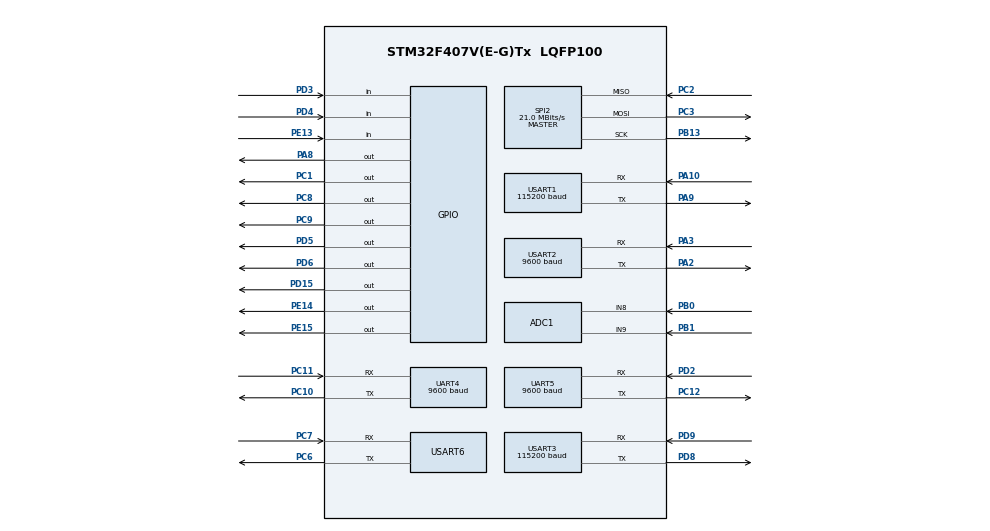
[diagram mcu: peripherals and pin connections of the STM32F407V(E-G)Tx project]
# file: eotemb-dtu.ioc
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ADC1.Channel-0\#ChannelRegularConversion=ADC_CHANNEL_8
ADC1.Channel-1\#ChannelRegularConversion=ADC_CHANNEL_9
ADC1.ClockPrescaler=ADC_CLOCK_SYNC_PCLK_DIV6
ADC1.ContinuousConvMode=ENABLE
ADC1.DMAContinuousRequests=ENABLE
ADC1.InjNumberOfConversion=0
ADC1.NbrOfConversion=2
ADC1.NbrOfConversionFlag=1
ADC1.Rank-0\#ChannelRegularConversion=1
ADC1.Rank-1\#ChannelRegularConversion=2
ADC1.SamplingTime-0\#ChannelRegularConversion=ADC_SAMPLETIME_480CYCLES
ADC1.SamplingTime-1\#ChannelRegularConversion=ADC_SAMPLETIME_480CYCLES
ADC1.master=1
Dma.ADC1.10.Direction=DMA_PERIPH_TO_MEMORY
Dma.ADC1.10.FIFOMode=DMA_FIFOMODE_DISABLE
Dma.ADC1.10.Instance=DMA2_Stream0
Dma.ADC1.10.MemDataAlignment=DMA_MDATAALIGN_HALFWORD
Dma.ADC1.10.MemInc=DMA_MINC_ENABLE
Dma.ADC1.10.Mode=DMA_CIRCULAR
Dma.ADC1.10.PeriphDataAlignment=DMA_PDATAALIGN_HALFWORD
Dma.ADC1.10.PeriphInc=DMA_PINC_DISABLE
Dma.ADC1.10.Priority=DMA_PRIORITY_LOW
Dma.Request0=USART1_RX
Dma.Request1=USART3_RX
Dma.Request10=ADC1
Dma.Request11=USART1_TX
Dma.Request2=USART6_RX
Dma.Request3=UART5_RX
Dma.Request4=UART4_RX
Dma.Request5=USART2_RX
Dma.Request6=UART5_TX
Dma.Request7=USART2_TX
Dma.Request8=USART3_TX
Dma.Request9=UART4_TX
Dma.UART4_RX.4.Direction=DMA_PERIPH_TO_MEMORY
Dma.UART4_RX.4.FIFOMode=DMA_FIFOMODE_DISABLE
Dma.UART4_RX.4.Instance=DMA1_Stream2
Dma.UART4_RX.4.MemDataAlignment=DMA_MDATAALIGN_BYTE
Dma.UART4_RX.4.MemInc=DMA_MINC_ENABLE
Dma.UART4_RX.4.Mode=DMA_NORMAL
Dma.UART4_RX.4.PeriphDataAlignment=DMA_PDATAALIGN_BYTE
Dma.UART4_RX.4.PeriphInc=DMA_PINC_DISABLE
Dma.UART4_RX.4.Priority=DMA_PRIORITY_LOW
Dma.UART4_TX.9.Direction=DMA_MEMORY_TO_PERIPH
Dma.UART4_TX.9.FIFOMode=DMA_FIFOMODE_DISABLE
Dma.UART4_TX.9.Instance=DMA1_Stream4
Dma.UART4_TX.9.MemDataAlignment=DMA_MDATAALIGN_BYTE
Dma.UART4_TX.9.MemInc=DMA_MINC_ENABLE
Dma.UART4_TX.9.Mode=DMA_NORMAL
Dma.UART4_TX.9.PeriphDataAlignment=DMA_PDATAALIGN_BYTE
Dma.UART4_TX.9.PeriphInc=DMA_PINC_DISABLE
Dma.UART4_TX.9.Priority=DMA_PRIORITY_LOW
Dma.UART5_RX.3.Direction=DMA_PERIPH_TO_MEMORY
Dma.UART5_RX.3.FIFOMode=DMA_FIFOMODE_DISABLE
Dma.UART5_RX.3.Instance=DMA1_Stream0
Dma.UART5_RX.3.MemDataAlignment=DMA_MDATAALIGN_BYTE
Dma.UART5_RX.3.MemInc=DMA_MINC_ENABLE
Dma.UART5_RX.3.Mode=DMA_NORMAL
Dma.UART5_RX.3.PeriphDataAlignment=DMA_PDATAALIGN_BYTE
Dma.UART5_RX.3.PeriphInc=DMA_PINC_DISABLE
Dma.UART5_RX.3.Priority=DMA_PRIORITY_LOW
Dma.UART5_TX.6.Direction=DMA_MEMORY_TO_PERIPH
Dma.UART5_TX.6.FIFOMode=DMA_FIFOMODE_DISABLE
Dma.UART5_TX.6.Instance=DMA1_Stream7
Dma.UART5_TX.6.MemDataAlignment=DMA_MDATAALIGN_BYTE
Dma.UART5_TX.6.MemInc=DMA_MINC_ENABLE
Dma.UART5_TX.6.Mode=DMA_NORMAL
Dma.UART5_TX.6.PeriphDataAlignment=DMA_PDATAALIGN_BYTE
Dma.UART5_TX.6.PeriphInc=DMA_PINC_DISABLE
Dma.UART5_TX.6.Priority=DMA_PRIORITY_LOW
Dma.USART1_RX.0.Direction=DMA_PERIPH_TO_MEMORY
Dma.USART1_RX.0.FIFOMode=DMA_FIFOMODE_DISABLE
Dma.USART1_RX.0.Instance=DMA2_Stream2
Dma.USART1_RX.0.MemDataAlignment=DMA_MDATAALIGN_BYTE
Dma.USART1_RX.0.MemInc=DMA_MINC_ENABLE
Dma.USART1_RX.0.Mode=DMA_NORMAL
Dma.USART1_RX.0.PeriphDataAlignment=DMA_PDATAALIGN_BYTE
Dma.USART1_RX.0.PeriphInc=DMA_PINC_DISABLE
Dma.USART1_RX.0.Priority=DMA_PRIORITY_LOW
Dma.USART1_TX.11.Direction=DMA_MEMORY_TO_PERIPH
Dma.USART1_TX.11.FIFOMode=DMA_FIFOMODE_DISABLE
Dma.USART1_TX.11.Instance=DMA2_Stream7
Dma.USART1_TX.11.MemDataAlignment=DMA_MDATAALIGN_BYTE
Dma.USART1_TX.11.MemInc=DMA_MINC_ENABLE
Dma.USART1_TX.11.Mode=DMA_NORMAL
Dma.USART1_TX.11.PeriphDataAlignment=DMA_PDATAALIGN_BYTE
Dma.USART1_TX.11.PeriphInc=DMA_PINC_DISABLE
Dma.USART1_TX.11.Priority=DMA_PRIORITY_LOW
Dma.USART2_RX.5.Direction=DMA_PERIPH_TO_MEMORY
Dma.USART2_RX.5.FIFOMode=DMA_FIFOMODE_DISABLE
Dma.USART2_RX.5.Instance=DMA1_Stream5
Dma.USART2_RX.5.MemDataAlignment=DMA_MDATAALIGN_BYTE
Dma.USART2_RX.5.MemInc=DMA_MINC_ENABLE
Dma.USART2_RX.5.Mode=DMA_NORMAL
Dma.USART2_RX.5.PeriphDataAlignment=DMA_PDATAALIGN_BYTE
Dma.USART2_RX.5.PeriphInc=DMA_PINC_DISABLE
Dma.USART2_RX.5.Priority=DMA_PRIORITY_LOW
Dma.USART2_TX.7.Direction=DMA_MEMORY_TO_PERIPH
Dma.USART2_TX.7.FIFOMode=DMA_FIFOMODE_DISABLE
Dma.USART2_TX.7.Instance=DMA1_Stream6
Dma.USART2_TX.7.MemDataAlignment=DMA_MDATAALIGN_BYTE
Dma.USART2_TX.7.MemInc=DMA_MINC_ENABLE
Dma.USART2_TX.7.Mode=DMA_NORMAL
Dma.USART2_TX.7.PeriphDataAlignment=DMA_PDATAALIGN_BYTE
Dma.USART2_TX.7.PeriphInc=DMA_PINC_DISABLE
Dma.USART2_TX.7.Priority=DMA_PRIORITY_LOW
Dma.USART3_RX.1.Direction=DMA_PERIPH_TO_MEMORY
Dma.USART3_RX.1.FIFOMode=DMA_FIFOMODE_DISABLE
Dma.USART3_RX.1.Instance=DMA1_Stream1
Dma.USART3_RX.1.MemDataAlignment=DMA_MDATAALIGN_BYTE
Dma.USART3_RX.1.MemInc=DMA_MINC_ENABLE
Dma.USART3_RX.1.Mode=DMA_NORMAL
Dma.USART3_RX.1.PeriphDataAlignment=DMA_PDATAALIGN_BYTE
Dma.USART3_RX.1.PeriphInc=DMA_PINC_DISABLE
Dma.USART3_RX.1.Priority=DMA_PRIORITY_LOW
Dma.USART3_TX.8.Direction=DMA_MEMORY_TO_PERIPH
Dma.USART3_TX.8.FIFOMode=DMA_FIFOMODE_DISABLE
Dma.USART3_TX.8.Instance=DMA1_Stream3
Dma.USART3_TX.8.MemDataAlignment=DMA_MDATAALIGN_BYTE
Dma.USART3_TX.8.MemInc=DMA_MINC_ENABLE
Dma.USART3_TX.8.Mode=DMA_NORMAL
Dma.USART3_TX.8.PeriphDataAlignment=DMA_PDATAALIGN_BYTE
Dma.USART3_TX.8.PeriphInc=DMA_PINC_DISABLE
Dma.USART3_TX.8.Priority=DMA_PRIORITY_LOW
Dma.USART6_RX.2.Direction=DMA_PERIPH_TO_MEMORY
Dma.USART6_RX.2.FIFOMode=DMA_FIFOMODE_DISABLE
Dma.USART6_RX.2.Instance=DMA2_Stream1
Dma.USART6_RX.2.MemDataAlignment=DMA_MDATAALIGN_BYTE
Dma.USART6_RX.2.MemInc=DMA_MINC_ENABLE
Dma.USART6_RX.2.Mode=DMA_NORMAL
Dma.USART6_RX.2.PeriphDataAlignment=DMA_PDATAALIGN_BYTE
Dma.USART6_RX.2.PeriphInc=DMA_PINC_DISABLE
Dma.USART6_RX.2.Priority=DMA_PRIORITY_LOW
FREERTOS.Tasks01=defaultTask,0,128,StartDefaultTask,Default,NULL,Dynamic,NULL,NULL
FREERTOS.configUSE_NEWLIB_REENTRANT=1
IWDG.Prescaler=IWDG_PRESCALER_256
Mcu.Family=STM32F4
Mcu.Name=STM32F407V(E-G)Tx
Mcu.Package=LQFP100
NVIC.DMA1_Stream0_IRQn=true\:5\:0\:false\:false\:true\:true\:false\:true\:true
NVIC.DMA1_Stream1_IRQn=true\:5\:0\:false\:false\:true\:true\:false\:true\:true
NVIC.DMA1_Stream2_IRQn=true\:5\:0\:false\:false\:true\:true\:false\:true\:true
NVIC.DMA1_Stream3_IRQn=true\:5\:0\:false\:false\:true\:true\:false\:true\:true
NVIC.DMA1_Stream4_IRQn=true\:5\:0\:false\:false\:true\:true\:false\:true\:true
NVIC.DMA1_Stream5_IRQn=true\:5\:0\:false\:false\:true\:true\:false\:true\:true
NVIC.DMA1_Stream6_IRQn=true\:5\:0\:false\:false\:true\:true\:false\:true\:true
NVIC.DMA1_Stream7_IRQn=true\:5\:0\:false\:false\:true\:true\:false\:true\:true
NVIC.DMA2_Stream0_IRQn=true\:5\:0\:false\:false\:true\:true\:false\:true\:true
NVIC.DMA2_Stream1_IRQn=true\:5\:0\:false\:false\:true\:true\:false\:true\:true
NVIC.DMA2_Stream2_IRQn=true\:5\:0\:false\:false\:true\:true\:false\:true\:true
NVIC.DMA2_Stream7_IRQn=true\:5\:0\:false\:false\:true\:true\:false\:true\:true
NVIC.PriorityGroup=NVIC_PRIORITYGROUP_4
NVIC.TIM8_TRG_COM_TIM14_IRQn=true\:15\:0\:false\:false\:true\:false\:false\:true\:true
NVIC.TimeBase=TIM8_TRG_COM_TIM14_IRQn
NVIC.TimeBaseIP=TIM14
PA10.Mode=Asynchronous
PA10.Signal=USART1_RX
PA2.Mode=Asynchronous
PA2.Signal=USART2_TX
PA3.Mode=Asynchronous
PA3.Signal=USART2_RX
PA8.GPIO_PuPd=GPIO_PULLDOWN
PA8.Signal=GPIO_Output
PA9.Mode=Asynchronous
PA9.Signal=USART1_TX
PB0.Signal=ADCx_IN8
PB1.Signal=ADCx_IN9
PB13.Mode=Full_Duplex_Master
PB13.Signal=SPI2_SCK
PC1.Signal=GPIO_Output
PC10.Mode=Asynchronous
PC10.Signal=UART4_TX
PC11.Mode=Asynchronous
PC11.Signal=UART4_RX
PC12.Mode=Asynchronous
PC12.Signal=UART5_TX
PC14-OSC32_IN.Mode=LSE-External-Oscillator
PC14-OSC32_IN.Signal=RCC_OSC32_IN
PC15-OSC32_OUT.Mode=LSE-External-Oscillator
PC15-OSC32_OUT.Signal=RCC_OSC32_OUT
PC2.Mode=Full_Duplex_Master
PC2.Signal=SPI2_MISO
PC3.Mode=Full_Duplex_Master
PC3.Signal=SPI2_MOSI
PC6.Mode=Asynchronous
PC6.Signal=USART6_TX
PC7.Mode=Asynchronous
PC7.Signal=USART6_RX
PC8.GPIO_PuPd=GPIO_PULLUP
PC8.PinState=GPIO_PIN_SET
PC8.Signal=GPIO_Output
PC9.GPIO_PuPd=GPIO_PULLDOWN
PC9.Signal=GPIO_Output
PD15.Signal=GPIO_Output
PD2.Mode=Asynchronous
PD2.Signal=UART5_RX
PD3.GPIO_PuPd=GPIO_PULLDOWN
PD3.Signal=GPIO_Input
PD4.GPIO_PuPd=GPIO_PULLDOWN
PD4.Signal=GPIO_Input
PD5.GPIO_PuPd=GPIO_PULLDOWN
PD5.Signal=GPIO_Output
PD6.GPIO_PuPd=GPIO_PULLDOWN
PD6.Signal=GPIO_Output
PD8.Mode=Asynchronous
PD8.Signal=USART3_TX
PD9.Mode=Asynchronous
PD9.Signal=USART3_RX
PE13.GPIO_PuPd=GPIO_PULLDOWN
PE13.Signal=GPIO_Input
PE14.GPIO_PuPd=GPIO_PULLDOWN
PE14.Signal=GPIO_Output
PE15.GPIO_PuPd=GPIO_PULLDOWN
PE15.PinState=GPIO_PIN_SET
PE15.Signal=GPIO_Output
PH0-OSC_IN.Mode=HSE-External-Oscillator
PH0-OSC_IN.Signal=RCC_OSC_IN
PH1-OSC_OUT.Mode=HSE-External-Oscillator
PH1-OSC_OUT.Signal=RCC_OSC_OUT
ProjectManager.HeapSize=0x8000
ProjectManager.StackSize=0x4000
ProjectManager.TargetToolchain=STM32CubeIDE
RCC.48MHZClocksFreq_Value=84000000
RCC.AHBFreq_Value=168000000
RCC.APB1CLKDivider=RCC_HCLK_DIV4
RCC.APB1Freq_Value=42000000
RCC.APB1TimFreq_Value=84000000
RCC.APB2CLKDivider=RCC_HCLK_DIV2
RCC.APB2Freq_Value=84000000
RCC.APB2TimFreq_Value=168000000
RCC.CortexFreq_Value=168000000
RCC.HCLKFreq_Value=168000000
RCC.HSE_VALUE=25000000
RCC.HSICalibrationValue=25
RCC.HSI_VALUE=16000000
RCC.PLLM=25
RCC.PLLN=336
RCC.PLLSourceVirtual=RCC_PLLSOURCE_HSE
RCC.RCC_RTC_Clock_SourceVirtual=RCC_RTCCLKSOURCE_LSE
RCC.SYSCLKFreq_VALUE=168000000
RCC.SYSCLKSource=RCC_SYSCLKSOURCE_PLLCLK
RCC.VCOOutputFreq_Value=336000000
SH.ADCx_IN8.0=ADC1_IN8,IN8
SH.ADCx_IN9.0=ADC1_IN9,IN9
SPI2.BaudRatePrescaler=SPI_BAUDRATEPRESCALER_2
SPI2.CLKPhase=SPI_PHASE_2EDGE
SPI2.CLKPolarity=SPI_POLARITY_HIGH
SPI2.CalculateBaudRate=21.0 MBits/s
SPI2.Direction=SPI_DIRECTION_2LINES
SPI2.Mode=SPI_MODE_MASTER
SPI2.VirtualType=VM_MASTER
TIM7.AutoReloadPreload=TIM_AUTORELOAD_PRELOAD_ENABLE
TIM7.Period=8399
TIM7.Prescaler=9
TIM7.TIM_MasterOutputTrigger=TIM_TRGO_UPDATE
UART4.BaudRate=9600
UART4.VirtualMode=Asynchronous
UART5.BaudRate=9600
UART5.VirtualMode=Asynchronous
USART1.BaudRate=115200
USART1.VirtualMode=VM_ASYNC
USART2.BaudRate=9600
USART2.VirtualMode=VM_ASYNC
USART3.BaudRate=115200
USART3.VirtualMode=VM_ASYNC
USART6.VirtualMode=VM_ASYNC
VP_CRC_VS_CRC.Mode=CRC_Activate
VP_FREERTOS_VS_CMSIS_V1.Mode=CMSIS_V1
VP_IWDG_VS_IWDG.Mode=IWDG_Activate
VP_RTC_VS_RTC_Activate.Mode=RTC_Enabled
VP_RTC_VS_RTC_Calendar.Mode=RTC_Calendar
VP_SYS_VS_tim14.Mode=TIM14
VP_TIM7_VS_ClockSourceINT.Mode=Enable_Timer
board=custom

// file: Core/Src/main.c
/* USER CODE BEGIN Header */
/**
  ******************************************************************************
  * @file           : main.c
  * @brief          : Main program body
  ******************************************************************************
  * @attention
  *
  * Copyright (c) 2023 STMicroelectronics.
  * All rights reserved.
  *
  * This software is licensed under terms that can be found in the LICENSE file
  * in the root directory of this software component.
  * If no LICENSE file comes with this software, it is provided AS-IS.
  *
  ******************************************************************************
  */
/* USER CODE END Header */
#include "main.h"
#include "cmsis_os.h"

/* USER CODE BEGIN Includes */
#include "AppMain.h"
/* USER CODE END Includes */

CRC_HandleTypeDef hcrc;

osThreadId defaultTaskHandle;

void SystemClock_Config(void);
static void MX_GPIO_Init(void);
static void MX_DMA_Init(void);
static void MX_USART3_UART_Init(void);
static void MX_TIM7_Init(void);
static void MX_USART1_UART_Init(void);
static void MX_SPI2_Init(void);
static void MX_CRC_Init(void);
static void MX_IWDG_Init(void);
static void MX_RTC_Init(void);
static void MX_UART4_Init(void);
static void MX_UART5_Init(void);
static void MX_USART2_UART_Init(void);
static void MX_USART6_UART_Init(void);
static void MX_ADC1_Init(void);
void StartDefaultTask(void const * argument);

int main(void)
{

  /* USER CODE BEGIN 1 */

	__enable_irq();
  /* USER CODE END 1 */

  /* MCU Configuration--------------------------------------------------------*/

  /* Reset of all peripherals, Initializes the Flash interface and the Systick. */
  HAL_Init();

  /* Configure the system clock */
  SystemClock_Config();

  /* Initialize all configured peripherals */
  MX_GPIO_Init();
  MX_DMA_Init();
  MX_USART3_UART_Init();
  MX_TIM7_Init();
  MX_USART1_UART_Init();
  MX_SPI2_Init();
  MX_CRC_Init();
  MX_IWDG_Init();
  MX_RTC_Init();
  MX_UART4_Init();
  MX_UART5_Init();
  MX_USART2_UART_Init();
  MX_USART6_UART_Init();
  MX_ADC1_Init();

  /* Create the thread(s) */
  /* definition and creation of defaultTask */
  osThreadDef(defaultTask, StartDefaultTask, osPriorityNormal, 0, 128);
  defaultTaskHandle = osThreadCreate(osThread(defaultTask), NULL);

  /* Start scheduler */
  osKernelStart();

  /* We should never get here as control is now taken by the scheduler */

  /* Infinite loop */
  while (1)
  {

  }
}

void SystemClock_Config(void)
{
  LL_FLASH_SetLatency(LL_FLASH_LATENCY_5);
  while(LL_FLASH_GetLatency()!= LL_FLASH_LATENCY_5)
  {
  }
  LL_PWR_SetRegulVoltageScaling(LL_PWR_REGU_VOLTAGE_SCALE1);
  LL_RCC_HSE_Enable();

   /* Wait till HSE is ready */
  while(LL_RCC_HSE_IsReady() != 1)
  {

  }
  LL_RCC_LSI_Enable();

   /* Wait till LSI is ready */
  while(LL_RCC_LSI_IsReady() != 1)
  {

  }
  LL_PWR_EnableBkUpAccess();
  LL_RCC_LSE_Enable();

   /* Wait till LSE is ready */
  while(LL_RCC_LSE_IsReady() != 1)
  {

  }
  LL_RCC_PLL_ConfigDomain_SYS(LL_RCC_PLLSOURCE_HSE, LL_RCC_PLLM_DIV_25, 336, LL_RCC_PLLP_DIV_2);
  LL_RCC_PLL_Enable();

   /* Wait till PLL is ready */
  while(LL_RCC_PLL_IsReady() != 1)
  {

  }
  while (LL_PWR_IsActiveFlag_VOS() == 0)
  {
  }
  LL_RCC_SetAHBPrescaler(LL_RCC_SYSCLK_DIV_1);
  LL_RCC_SetAPB1Prescaler(LL_RCC_APB1_DIV_4);
  LL_RCC_SetAPB2Prescaler(LL_RCC_APB2_DIV_2);
  LL_RCC_SetSysClkSource(LL_RCC_SYS_CLKSOURCE_PLL);

   /* Wait till System clock is ready */
  while(LL_RCC_GetSysClkSource() != LL_RCC_SYS_CLKSOURCE_STATUS_PLL)
  {

  }
  LL_SetSystemCoreClock(168000000);

   /* Update the time base */
  if (HAL_InitTick (TICK_INT_PRIORITY) != HAL_OK)
  {
    Error_Handler();
  }
}

static void MX_ADC1_Init(void)
{

  LL_ADC_InitTypeDef ADC_InitStruct = {0};
  LL_ADC_REG_InitTypeDef ADC_REG_InitStruct = {0};
  LL_ADC_CommonInitTypeDef ADC_CommonInitStruct = {0};

  LL_GPIO_InitTypeDef GPIO_InitStruct = {0};

  /* Peripheral clock enable */
  LL_APB2_GRP1_EnableClock(LL_APB2_GRP1_PERIPH_ADC1);

  LL_AHB1_GRP1_EnableClock(LL_AHB1_GRP1_PERIPH_GPIOB);
  /**ADC1 GPIO Configuration
  PB0   ------> ADC1_IN8
  PB1   ------> ADC1_IN9
  */
  GPIO_InitStruct.Pin = LL_GPIO_PIN_0|LL_GPIO_PIN_1;
  GPIO_InitStruct.Mode = LL_GPIO_MODE_ANALOG;
  GPIO_InitStruct.Pull = LL_GPIO_PULL_NO;
  LL_GPIO_Init(GPIOB, &GPIO_InitStruct);

  /* ADC1 DMA Init */

  /* ADC1 Init */
  LL_DMA_SetChannelSelection(DMA2, LL_DMA_STREAM_0, LL_DMA_CHANNEL_0);

  LL_DMA_SetDataTransferDirection(DMA2, LL_DMA_STREAM_0, LL_DMA_DIRECTION_PERIPH_TO_MEMORY);

  LL_DMA_SetStreamPriorityLevel(DMA2, LL_DMA_STREAM_0, LL_DMA_PRIORITY_LOW);

  LL_DMA_SetMode(DMA2, LL_DMA_STREAM_0, LL_DMA_MODE_CIRCULAR);

  LL_DMA_SetPeriphIncMode(DMA2, LL_DMA_STREAM_0, LL_DMA_PERIPH_NOINCREMENT);

  LL_DMA_SetMemoryIncMode(DMA2, LL_DMA_STREAM_0, LL_DMA_MEMORY_INCREMENT);

  LL_DMA_SetPeriphSize(DMA2, LL_DMA_STREAM_0, LL_DMA_PDATAALIGN_HALFWORD);

  LL_DMA_SetMemorySize(DMA2, LL_DMA_STREAM_0, LL_DMA_MDATAALIGN_HALFWORD);

  LL_DMA_DisableFifoMode(DMA2, LL_DMA_STREAM_0);

  /** Common config
  */
  ADC_InitStruct.Resolution = LL_ADC_RESOLUTION_12B;
  ADC_InitStruct.DataAlignment = LL_ADC_DATA_ALIGN_RIGHT;
  ADC_InitStruct.SequencersScanMode = LL_ADC_SEQ_SCAN_ENABLE;
  LL_ADC_Init(ADC1, &ADC_InitStruct);
  ADC_REG_InitStruct.TriggerSource = LL_ADC_REG_TRIG_SOFTWARE;
  ADC_REG_InitStruct.SequencerLength = LL_ADC_REG_SEQ_SCAN_ENABLE_2RANKS;
  ADC_REG_InitStruct.SequencerDiscont = LL_ADC_REG_SEQ_DISCONT_DISABLE;
  ADC_REG_InitStruct.ContinuousMode = LL_ADC_REG_CONV_CONTINUOUS;
  ADC_REG_InitStruct.DMATransfer = LL_ADC_REG_DMA_TRANSFER_UNLIMITED;
  LL_ADC_REG_Init(ADC1, &ADC_REG_InitStruct);
  LL_ADC_REG_SetFlagEndOfConversion(ADC1, LL_ADC_REG_FLAG_EOC_UNITARY_CONV);
  ADC_CommonInitStruct.CommonClock = LL_ADC_CLOCK_SYNC_PCLK_DIV6;
  ADC_CommonInitStruct.Multimode = LL_ADC_MULTI_INDEPENDENT;
  LL_ADC_CommonInit(__LL_ADC_COMMON_INSTANCE(ADC1), &ADC_CommonInitStruct);

  /** Configure Regular Channel
  */
  LL_ADC_REG_SetSequencerRanks(ADC1, LL_ADC_REG_RANK_1, LL_ADC_CHANNEL_8);
  LL_ADC_SetChannelSamplingTime(ADC1, LL_ADC_CHANNEL_8, LL_ADC_SAMPLINGTIME_480CYCLES);

  /** Configure Regular Channel
  */
  LL_ADC_REG_SetSequencerRanks(ADC1, LL_ADC_REG_RANK_2, LL_ADC_CHANNEL_9);
  LL_ADC_SetChannelSamplingTime(ADC1, LL_ADC_CHANNEL_9, LL_ADC_SAMPLINGTIME_480CYCLES);

}

static void MX_CRC_Init(void)
{

  hcrc.Instance = CRC;
  if (HAL_CRC_Init(&hcrc) != HAL_OK)
  {
    Error_Handler();
  }

}

static void MX_IWDG_Init(void)
{

  LL_IWDG_Enable(IWDG);
  LL_IWDG_EnableWriteAccess(IWDG);
  LL_IWDG_SetPrescaler(IWDG, LL_IWDG_PRESCALER_256);
  LL_IWDG_SetReloadCounter(IWDG, 4095);
  while (LL_IWDG_IsReady(IWDG) != 1)
  {
  }

  LL_IWDG_ReloadCounter(IWDG);

}

static void MX_RTC_Init(void)
{

  LL_RTC_InitTypeDef RTC_InitStruct = {0};
  LL_RTC_TimeTypeDef RTC_TimeStruct = {0};
  LL_RTC_DateTypeDef RTC_DateStruct = {0};

  if(LL_RCC_GetRTCClockSource() != LL_RCC_RTC_CLKSOURCE_LSE)
  {
    FlagStatus pwrclkchanged = RESET;
    /* Update LSE configuration in Backup Domain control register */
    /* Requires to enable write access to Backup Domain if necessary */
    if (LL_APB1_GRP1_IsEnabledClock (LL_APB1_GRP1_PERIPH_PWR) != 1U)
    {
      /* Enables the PWR Clock and Enables access to the backup domain */
      LL_APB1_GRP1_EnableClock(LL_APB1_GRP1_PERIPH_PWR);
      pwrclkchanged = SET;
    }
    if (LL_PWR_IsEnabledBkUpAccess () != 1U)
    {
      /* Enable write access to Backup domain */
      LL_PWR_EnableBkUpAccess();
      while (LL_PWR_IsEnabledBkUpAccess () == 0U)
      {
      }
    }
    LL_RCC_ForceBackupDomainReset();
    LL_RCC_ReleaseBackupDomainReset();
    LL_RCC_LSE_Enable();

   /* Wait till LSE is ready */
    while(LL_RCC_LSE_IsReady() != 1)
    {
    }
  LL_RCC_SetRTCClockSource(LL_RCC_RTC_CLKSOURCE_LSE);
    /* Restore clock configuration if changed */
    if (pwrclkchanged == SET)
    {
      LL_APB1_GRP1_DisableClock(LL_APB1_GRP1_PERIPH_PWR);
    }
  }

  /* Peripheral clock enable */
  LL_RCC_EnableRTC();

  /** Initialize RTC and set the Time and Date
  */
  RTC_InitStruct.HourFormat = LL_RTC_HOURFORMAT_24HOUR;
  RTC_InitStruct.AsynchPrescaler = 127;
  RTC_InitStruct.SynchPrescaler = 255;
  LL_RTC_Init(RTC, &RTC_InitStruct);
  LL_RTC_SetAsynchPrescaler(RTC, 127);
  LL_RTC_SetSynchPrescaler(RTC, 255);

  /** Initialize RTC and set the Time and Date
  */
  if(LL_RTC_BAK_GetRegister(RTC, LL_RTC_BKP_DR0) != 0x32F2){

  RTC_TimeStruct.Hours = 0;
  RTC_TimeStruct.Minutes = 0;
  RTC_TimeStruct.Seconds = 0;
  LL_RTC_TIME_Init(RTC, LL_RTC_FORMAT_BCD, &RTC_TimeStruct);
  RTC_DateStruct.WeekDay = LL_RTC_WEEKDAY_MONDAY;
  RTC_DateStruct.Month = LL_RTC_MONTH_JANUARY;
  RTC_DateStruct.Day = 0x1;
  RTC_DateStruct.Year = 0;
  LL_RTC_DATE_Init(RTC, LL_RTC_FORMAT_BCD, &RTC_DateStruct);
    LL_RTC_BAK_SetRegister(RTC,LL_RTC_BKP_DR0,0x32F2);
  }

}

static void MX_SPI2_Init(void)
{

  LL_SPI_InitTypeDef SPI_InitStruct = {0};

  LL_GPIO_InitTypeDef GPIO_InitStruct = {0};

  /* Peripheral clock enable */
  LL_APB1_GRP1_EnableClock(LL_APB1_GRP1_PERIPH_SPI2);

  LL_AHB1_GRP1_EnableClock(LL_AHB1_GRP1_PERIPH_GPIOC);
  LL_AHB1_GRP1_EnableClock(LL_AHB1_GRP1_PERIPH_GPIOB);
  /**SPI2 GPIO Configuration
  PC2   ------> SPI2_MISO
  PC3   ------> SPI2_MOSI
  PB13   ------> SPI2_SCK
  */
  GPIO_InitStruct.Pin = LL_GPIO_PIN_2|LL_GPIO_PIN_3;
  GPIO_InitStruct.Mode = LL_GPIO_MODE_ALTERNATE;
  GPIO_InitStruct.Speed = LL_GPIO_SPEED_FREQ_VERY_HIGH;
  GPIO_InitStruct.OutputType = LL_GPIO_OUTPUT_PUSHPULL;
  GPIO_InitStruct.Pull = LL_GPIO_PULL_NO;
  GPIO_InitStruct.Alternate = LL_GPIO_AF_5;
  LL_GPIO_Init(GPIOC, &GPIO_InitStruct);

  GPIO_InitStruct.Pin = LL_GPIO_PIN_13;
  GPIO_InitStruct.Mode = LL_GPIO_MODE_ALTERNATE;
  GPIO_InitStruct.Speed = LL_GPIO_SPEED_FREQ_VERY_HIGH;
  GPIO_InitStruct.OutputType = LL_GPIO_OUTPUT_PUSHPULL;
  GPIO_InitStruct.Pull = LL_GPIO_PULL_NO;
  GPIO_InitStruct.Alternate = LL_GPIO_AF_5;
  LL_GPIO_Init(GPIOB, &GPIO_InitStruct);

  /* SPI2 parameter configuration*/
  SPI_InitStruct.TransferDirection = LL_SPI_FULL_DUPLEX;
  SPI_InitStruct.Mode = LL_SPI_MODE_MASTER;
  SPI_InitStruct.DataWidth = LL_SPI_DATAWIDTH_8BIT;
  SPI_InitStruct.ClockPolarity = LL_SPI_POLARITY_HIGH;
  SPI_InitStruct.ClockPhase = LL_SPI_PHASE_2EDGE;
  SPI_InitStruct.NSS = LL_SPI_NSS_SOFT;
  SPI_InitStruct.BaudRate = LL_SPI_BAUDRATEPRESCALER_DIV2;
  SPI_InitStruct.BitOrder = LL_SPI_MSB_FIRST;
  SPI_InitStruct.CRCCalculation = LL_SPI_CRCCALCULATION_DISABLE;
  SPI_InitStruct.CRCPoly = 10;
  LL_SPI_Init(SPI2, &SPI_InitStruct);
  LL_SPI_SetStandard(SPI2, LL_SPI_PROTOCOL_MOTOROLA);

}

static void MX_TIM7_Init(void)
{

  LL_TIM_InitTypeDef TIM_InitStruct = {0};

  /* Peripheral clock enable */
  LL_APB1_GRP1_EnableClock(LL_APB1_GRP1_PERIPH_TIM7);

  TIM_InitStruct.Prescaler = 9;
  TIM_InitStruct.CounterMode = LL_TIM_COUNTERMODE_UP;
  TIM_InitStruct.Autoreload = 8399;
  LL_TIM_Init(TIM7, &TIM_InitStruct);
  LL_TIM_EnableARRPreload(TIM7);
  LL_TIM_SetTriggerOutput(TIM7, LL_TIM_TRGO_UPDATE);
  LL_TIM_DisableMasterSlaveMode(TIM7);
  /* USER CODE BEGIN TIM7_Init 2 */

  NVIC_SetPriority(TIM7_IRQn, NVIC_EncodePriority(NVIC_GetPriorityGrouping(),5, 0));
  NVIC_EnableIRQ(TIM7_IRQn);

  LL_TIM_EnableIT_UPDATE(TIM7);
  LL_TIM_EnableCounter(TIM7);

  /* USER CODE END TIM7_Init 2 */

}

static void MX_UART4_Init(void)
{

  LL_USART_InitTypeDef USART_InitStruct = {0};

  LL_GPIO_InitTypeDef GPIO_InitStruct = {0};

  /* Peripheral clock enable */
  LL_APB1_GRP1_EnableClock(LL_APB1_GRP1_PERIPH_UART4);

  LL_AHB1_GRP1_EnableClock(LL_AHB1_GRP1_PERIPH_GPIOC);
  /**UART4 GPIO Configuration
  PC10   ------> UART4_TX
  PC11   ------> UART4_RX
  */
  GPIO_InitStruct.Pin = LL_GPIO_PIN_10|LL_GPIO_PIN_11;
  GPIO_InitStruct.Mode = LL_GPIO_MODE_ALTERNATE;
  GPIO_InitStruct.Speed = LL_GPIO_SPEED_FREQ_VERY_HIGH;
  GPIO_InitStruct.OutputType = LL_GPIO_OUTPUT_PUSHPULL;
  GPIO_InitStruct.Pull = LL_GPIO_PULL_NO;
  GPIO_InitStruct.Alternate = LL_GPIO_AF_8;
  LL_GPIO_Init(GPIOC, &GPIO_InitStruct);

  /* UART4 DMA Init */

  /* UART4_RX Init */
  LL_DMA_SetChannelSelection(DMA1, LL_DMA_STREAM_2, LL_DMA_CHANNEL_4);

  LL_DMA_SetDataTransferDirection(DMA1, LL_DMA_STREAM_2, LL_DMA_DIRECTION_PERIPH_TO_MEMORY);

  LL_DMA_SetStreamPriorityLevel(DMA1, LL_DMA_STREAM_2, LL_DMA_PRIORITY_LOW);

  LL_DMA_SetMode(DMA1, LL_DMA_STREAM_2, LL_DMA_MODE_NORMAL);

  LL_DMA_SetPeriphIncMode(DMA1, LL_DMA_STREAM_2, LL_DMA_PERIPH_NOINCREMENT);

  LL_DMA_SetMemoryIncMode(DMA1, LL_DMA_STREAM_2, LL_DMA_MEMORY_INCREMENT);

  LL_DMA_SetPeriphSize(DMA1, LL_DMA_STREAM_2, LL_DMA_PDATAALIGN_BYTE);

  LL_DMA_SetMemorySize(DMA1, LL_DMA_STREAM_2, LL_DMA_MDATAALIGN_BYTE);

  LL_DMA_DisableFifoMode(DMA1, LL_DMA_STREAM_2);

  /* UART4_TX Init */
  LL_DMA_SetChannelSelection(DMA1, LL_DMA_STREAM_4, LL_DMA_CHANNEL_4);

  LL_DMA_SetDataTransferDirection(DMA1, LL_DMA_STREAM_4, LL_DMA_DIRECTION_MEMORY_TO_PERIPH);

  LL_DMA_SetStreamPriorityLevel(DMA1, LL_DMA_STREAM_4, LL_DMA_PRIORITY_LOW);

  LL_DMA_SetMode(DMA1, LL_DMA_STREAM_4, LL_DMA_MODE_NORMAL);

  LL_DMA_SetPeriphIncMode(DMA1, LL_DMA_STREAM_4, LL_DMA_PERIPH_NOINCREMENT);

  LL_DMA_SetMemoryIncMode(DMA1, LL_DMA_STREAM_4, LL_DMA_MEMORY_INCREMENT);

  LL_DMA_SetPeriphSize(DMA1, LL_DMA_STREAM_4, LL_DMA_PDATAALIGN_BYTE);

  LL_DMA_SetMemorySize(DMA1, LL_DMA_STREAM_4, LL_DMA_MDATAALIGN_BYTE);

  LL_DMA_DisableFifoMode(DMA1, LL_DMA_STREAM_4);

  USART_InitStruct.BaudRate = 9600;
  USART_InitStruct.DataWidth = LL_USART_DATAWIDTH_8B;
  USART_InitStruct.StopBits = LL_USART_STOPBITS_1;
  USART_InitStruct.Parity = LL_USART_PARITY_NONE;
  USART_InitStruct.TransferDirection = LL_USART_DIRECTION_TX_RX;
  USART_InitStruct.HardwareFlowControl = LL_USART_HWCONTROL_NONE;
  USART_InitStruct.OverSampling = LL_USART_OVERSAMPLING_16;
  LL_USART_Init(UART4, &USART_InitStruct);
  LL_USART_ConfigAsyncMode(UART4);
  LL_USART_Enable(UART4);

}

static void MX_UART5_Init(void)
{

  LL_USART_InitTypeDef USART_InitStruct = {0};

  LL_GPIO_InitTypeDef GPIO_InitStruct = {0};

  /* Peripheral clock enable */
  LL_APB1_GRP1_EnableClock(LL_APB1_GRP1_PERIPH_UART5);

  LL_AHB1_GRP1_EnableClock(LL_AHB1_GRP1_PERIPH_GPIOC);
  LL_AHB1_GRP1_EnableClock(LL_AHB1_GRP1_PERIPH_GPIOD);
  /**UART5 GPIO Configuration
  PC12   ------> UART5_TX
  PD2   ------> UART5_RX
  */
  GPIO_InitStruct.Pin = LL_GPIO_PIN_12;
  GPIO_InitStruct.Mode = LL_GPIO_MODE_ALTERNATE;
  GPIO_InitStruct.Speed = LL_GPIO_SPEED_FREQ_VERY_HIGH;
  GPIO_InitStruct.OutputType = LL_GPIO_OUTPUT_PUSHPULL;
  GPIO_InitStruct.Pull = LL_GPIO_PULL_NO;
  GPIO_InitStruct.Alternate = LL_GPIO_AF_8;
  LL_GPIO_Init(GPIOC, &GPIO_InitStruct);

  GPIO_InitStruct.Pin = LL_GPIO_PIN_2;
  GPIO_InitStruct.Mode = LL_GPIO_MODE_ALTERNATE;
  GPIO_InitStruct.Speed = LL_GPIO_SPEED_FREQ_VERY_HIGH;
  GPIO_InitStruct.OutputType = LL_GPIO_OUTPUT_PUSHPULL;
  GPIO_InitStruct.Pull = LL_GPIO_PULL_NO;
  GPIO_InitStruct.Alternate = LL_GPIO_AF_8;
  LL_GPIO_Init(GPIOD, &GPIO_InitStruct);

  /* UART5 DMA Init */

  /* UART5_RX Init */
  LL_DMA_SetChannelSelection(DMA1, LL_DMA_STREAM_0, LL_DMA_CHANNEL_4);

  LL_DMA_SetDataTransferDirection(DMA1, LL_DMA_STREAM_0, LL_DMA_DIRECTION_PERIPH_TO_MEMORY);

  LL_DMA_SetStreamPriorityLevel(DMA1, LL_DMA_STREAM_0, LL_DMA_PRIORITY_LOW);

  LL_DMA_SetMode(DMA1, LL_DMA_STREAM_0, LL_DMA_MODE_NORMAL);

  LL_DMA_SetPeriphIncMode(DMA1, LL_DMA_STREAM_0, LL_DMA_PERIPH_NOINCREMENT);

  LL_DMA_SetMemoryIncMode(DMA1, LL_DMA_STREAM_0, LL_DMA_MEMORY_INCREMENT);

  LL_DMA_SetPeriphSize(DMA1, LL_DMA_STREAM_0, LL_DMA_PDATAALIGN_BYTE);

  LL_DMA_SetMemorySize(DMA1, LL_DMA_STREAM_0, LL_DMA_MDATAALIGN_BYTE);

  LL_DMA_DisableFifoMode(DMA1, LL_DMA_STREAM_0);

  /* UART5_TX Init */
  LL_DMA_SetChannelSelection(DMA1, LL_DMA_STREAM_7, LL_DMA_CHANNEL_4);

  LL_DMA_SetDataTransferDirection(DMA1, LL_DMA_STREAM_7, LL_DMA_DIRECTION_MEMORY_TO_PERIPH);

  LL_DMA_SetStreamPriorityLevel(DMA1, LL_DMA_STREAM_7, LL_DMA_PRIORITY_LOW);

  LL_DMA_SetMode(DMA1, LL_DMA_STREAM_7, LL_DMA_MODE_NORMAL);

  LL_DMA_SetPeriphIncMode(DMA1, LL_DMA_STREAM_7, LL_DMA_PERIPH_NOINCREMENT);

  LL_DMA_SetMemoryIncMode(DMA1, LL_DMA_STREAM_7, LL_DMA_MEMORY_INCREMENT);

  LL_DMA_SetPeriphSize(DMA1, LL_DMA_STREAM_7, LL_DMA_PDATAALIGN_BYTE);

  LL_DMA_SetMemorySize(DMA1, LL_DMA_STREAM_7, LL_DMA_MDATAALIGN_BYTE);

  LL_DMA_DisableFifoMode(DMA1, LL_DMA_STREAM_7);

  USART_InitStruct.BaudRate = 9600;
  USART_InitStruct.DataWidth = LL_USART_DATAWIDTH_8B;
  USART_InitStruct.StopBits = LL_USART_STOPBITS_1;
  USART_InitStruct.Parity = LL_USART_PARITY_NONE;
  USART_InitStruct.TransferDirection = LL_USART_DIRECTION_TX_RX;
  USART_InitStruct.HardwareFlowControl = LL_USART_HWCONTROL_NONE;
  USART_InitStruct.OverSampling = LL_USART_OVERSAMPLING_16;
  LL_USART_Init(UART5, &USART_InitStruct);
  LL_USART_ConfigAsyncMode(UART5);
  LL_USART_Enable(UART5);

}

static void MX_USART1_UART_Init(void)
{

  LL_USART_InitTypeDef USART_InitStruct = {0};

  LL_GPIO_InitTypeDef GPIO_InitStruct = {0};

  /* Peripheral clock enable */
  LL_APB2_GRP1_EnableClock(LL_APB2_GRP1_PERIPH_USART1);

  LL_AHB1_GRP1_EnableClock(LL_AHB1_GRP1_PERIPH_GPIOA);
  /**USART1 GPIO Configuration
  PA9   ------> USART1_TX
  PA10   ------> USART1_RX
  */
  GPIO_InitStruct.Pin = LL_GPIO_PIN_9|LL_GPIO_PIN_10;
  GPIO_InitStruct.Mode = LL_GPIO_MODE_ALTERNATE;
  GPIO_InitStruct.Speed = LL_GPIO_SPEED_FREQ_VERY_HIGH;
  GPIO_InitStruct.OutputType = LL_GPIO_OUTPUT_PUSHPULL;
  GPIO_InitStruct.Pull = LL_GPIO_PULL_NO;
  GPIO_InitStruct.Alternate = LL_GPIO_AF_7;
  LL_GPIO_Init(GPIOA, &GPIO_InitStruct);

  /* USART1 DMA Init */

  /* USART1_RX Init */
  LL_DMA_SetChannelSelection(DMA2, LL_DMA_STREAM_2, LL_DMA_CHANNEL_4);

  LL_DMA_SetDataTransferDirection(DMA2, LL_DMA_STREAM_2, LL_DMA_DIRECTION_PERIPH_TO_MEMORY);

  LL_DMA_SetStreamPriorityLevel(DMA2, LL_DMA_STREAM_2, LL_DMA_PRIORITY_LOW);

  LL_DMA_SetMode(DMA2, LL_DMA_STREAM_2, LL_DMA_MODE_NORMAL);

  LL_DMA_SetPeriphIncMode(DMA2, LL_DMA_STREAM_2, LL_DMA_PERIPH_NOINCREMENT);

  LL_DMA_SetMemoryIncMode(DMA2, LL_DMA_STREAM_2, LL_DMA_MEMORY_INCREMENT);

  LL_DMA_SetPeriphSize(DMA2, LL_DMA_STREAM_2, LL_DMA_PDATAALIGN_BYTE);

  LL_DMA_SetMemorySize(DMA2, LL_DMA_STREAM_2, LL_DMA_MDATAALIGN_BYTE);

  LL_DMA_DisableFifoMode(DMA2, LL_DMA_STREAM_2);

  /* USART1_TX Init */
  LL_DMA_SetChannelSelection(DMA2, LL_DMA_STREAM_7, LL_DMA_CHANNEL_4);

  LL_DMA_SetDataTransferDirection(DMA2, LL_DMA_STREAM_7, LL_DMA_DIRECTION_MEMORY_TO_PERIPH);

  LL_DMA_SetStreamPriorityLevel(DMA2, LL_DMA_STREAM_7, LL_DMA_PRIORITY_LOW);

  LL_DMA_SetMode(DMA2, LL_DMA_STREAM_7, LL_DMA_MODE_NORMAL);

  LL_DMA_SetPeriphIncMode(DMA2, LL_DMA_STREAM_7, LL_DMA_PERIPH_NOINCREMENT);

  LL_DMA_SetMemoryIncMode(DMA2, LL_DMA_STREAM_7, LL_DMA_MEMORY_INCREMENT);

  LL_DMA_SetPeriphSize(DMA2, LL_DMA_STREAM_7, LL_DMA_PDATAALIGN_BYTE);

  LL_DMA_SetMemorySize(DMA2, LL_DMA_STREAM_7, LL_DMA_MDATAALIGN_BYTE);

  LL_DMA_DisableFifoMode(DMA2, LL_DMA_STREAM_7);

  /* USER CODE BEGIN USART1_Init 1 */
  //NVIC_SetPriority(USART1_IRQn, NVIC_EncodePriority(NVIC_GetPriorityGrouping(),5, 0));
  //NVIC_EnableIRQ(USART1_IRQn);
  /* USER CODE END USART1_Init 1 */
  USART_InitStruct.BaudRate = 115200;
  USART_InitStruct.DataWidth = LL_USART_DATAWIDTH_8B;
  USART_InitStruct.StopBits = LL_USART_STOPBITS_1;
  USART_InitStruct.Parity = LL_USART_PARITY_NONE;
  USART_InitStruct.TransferDirection = LL_USART_DIRECTION_TX_RX;
  USART_InitStruct.HardwareFlowControl = LL_USART_HWCONTROL_NONE;
  USART_InitStruct.OverSampling = LL_USART_OVERSAMPLING_16;
  LL_USART_Init(USART1, &USART_InitStruct);
  LL_USART_ConfigAsyncMode(USART1);
  LL_USART_Enable(USART1);

}

static void MX_USART2_UART_Init(void)
{

  LL_USART_InitTypeDef USART_InitStruct = {0};

  LL_GPIO_InitTypeDef GPIO_InitStruct = {0};

  /* Peripheral clock enable */
  LL_APB1_GRP1_EnableClock(LL_APB1_GRP1_PERIPH_USART2);

  LL_AHB1_GRP1_EnableClock(LL_AHB1_GRP1_PERIPH_GPIOA);
  /**USART2 GPIO Configuration
  PA2   ------> USART2_TX
  PA3   ------> USART2_RX
  */
  GPIO_InitStruct.Pin = LL_GPIO_PIN_2|LL_GPIO_PIN_3;
  GPIO_InitStruct.Mode = LL_GPIO_MODE_ALTERNATE;
  GPIO_InitStruct.Speed = LL_GPIO_SPEED_FREQ_VERY_HIGH;
  GPIO_InitStruct.OutputType = LL_GPIO_OUTPUT_PUSHPULL;
  GPIO_InitStruct.Pull = LL_GPIO_PULL_NO;
  GPIO_InitStruct.Alternate = LL_GPIO_AF_7;
  LL_GPIO_Init(GPIOA, &GPIO_InitStruct);

  /* USART2 DMA Init */

  /* USART2_RX Init */
  LL_DMA_SetChannelSelection(DMA1, LL_DMA_STREAM_5, LL_DMA_CHANNEL_4);

  LL_DMA_SetDataTransferDirection(DMA1, LL_DMA_STREAM_5, LL_DMA_DIRECTION_PERIPH_TO_MEMORY);

  LL_DMA_SetStreamPriorityLevel(DMA1, LL_DMA_STREAM_5, LL_DMA_PRIORITY_LOW);

  LL_DMA_SetMode(DMA1, LL_DMA_STREAM_5, LL_DMA_MODE_NORMAL);

  LL_DMA_SetPeriphIncMode(DMA1, LL_DMA_STREAM_5, LL_DMA_PERIPH_NOINCREMENT);

  LL_DMA_SetMemoryIncMode(DMA1, LL_DMA_STREAM_5, LL_DMA_MEMORY_INCREMENT);

  LL_DMA_SetPeriphSize(DMA1, LL_DMA_STREAM_5, LL_DMA_PDATAALIGN_BYTE);

  LL_DMA_SetMemorySize(DMA1, LL_DMA_STREAM_5, LL_DMA_MDATAALIGN_BYTE);

  LL_DMA_DisableFifoMode(DMA1, LL_DMA_STREAM_5);

  /* USART2_TX Init */
  LL_DMA_SetChannelSelection(DMA1, LL_DMA_STREAM_6, LL_DMA_CHANNEL_4);

  LL_DMA_SetDataTransferDirection(DMA1, LL_DMA_STREAM_6, LL_DMA_DIRECTION_MEMORY_TO_PERIPH);

  LL_DMA_SetStreamPriorityLevel(DMA1, LL_DMA_STREAM_6, LL_DMA_PRIORITY_LOW);

  LL_DMA_SetMode(DMA1, LL_DMA_STREAM_6, LL_DMA_MODE_NORMAL);

  LL_DMA_SetPeriphIncMode(DMA1, LL_DMA_STREAM_6, LL_DMA_PERIPH_NOINCREMENT);

  LL_DMA_SetMemoryIncMode(DMA1, LL_DMA_STREAM_6, LL_DMA_MEMORY_INCREMENT);

  LL_DMA_SetPeriphSize(DMA1, LL_DMA_STREAM_6, LL_DMA_PDATAALIGN_BYTE);

  LL_DMA_SetMemorySize(DMA1, LL_DMA_STREAM_6, LL_DMA_MDATAALIGN_BYTE);

  LL_DMA_DisableFifoMode(DMA1, LL_DMA_STREAM_6);

  USART_InitStruct.BaudRate = 9600;
  USART_InitStruct.DataWidth = LL_USART_DATAWIDTH_8B;
  USART_InitStruct.StopBits = LL_USART_STOPBITS_1;
  USART_InitStruct.Parity = LL_USART_PARITY_NONE;
  USART_InitStruct.TransferDirection = LL_USART_DIRECTION_TX_RX;
  USART_InitStruct.HardwareFlowControl = LL_USART_HWCONTROL_NONE;
  USART_InitStruct.OverSampling = LL_USART_OVERSAMPLING_16;
  LL_USART_Init(USART2, &USART_InitStruct);
  LL_USART_ConfigAsyncMode(USART2);
  LL_USART_Enable(USART2);

}

static void MX_USART3_UART_Init(void)
{

  LL_USART_InitTypeDef USART_InitStruct = {0};

  LL_GPIO_InitTypeDef GPIO_InitStruct = {0};

  /* Peripheral clock enable */
  LL_APB1_GRP1_EnableClock(LL_APB1_GRP1_PERIPH_USART3);

  LL_AHB1_GRP1_EnableClock(LL_AHB1_GRP1_PERIPH_GPIOD);
  /**USART3 GPIO Configuration
  PD8   ------> USART3_TX
  PD9   ------> USART3_RX
  */
  GPIO_InitStruct.Pin = LL_GPIO_PIN_8|LL_GPIO_PIN_9;
  GPIO_InitStruct.Mode = LL_GPIO_MODE_ALTERNATE;
  GPIO_InitStruct.Speed = LL_GPIO_SPEED_FREQ_VERY_HIGH;
  GPIO_InitStruct.OutputType = LL_GPIO_OUTPUT_PUSHPULL;
  GPIO_InitStruct.Pull = LL_GPIO_PULL_NO;
  GPIO_InitStruct.Alternate = LL_GPIO_AF_7;
  LL_GPIO_Init(GPIOD, &GPIO_InitStruct);

  /* USART3 DMA Init */

  /* USART3_RX Init */
  LL_DMA_SetChannelSelection(DMA1, LL_DMA_STREAM_1, LL_DMA_CHANNEL_4);

  LL_DMA_SetDataTransferDirection(DMA1, LL_DMA_STREAM_1, LL_DMA_DIRECTION_PERIPH_TO_MEMORY);

  LL_DMA_SetStreamPriorityLevel(DMA1, LL_DMA_STREAM_1, LL_DMA_PRIORITY_LOW);

  LL_DMA_SetMode(DMA1, LL_DMA_STREAM_1, LL_DMA_MODE_NORMAL);

  LL_DMA_SetPeriphIncMode(DMA1, LL_DMA_STREAM_1, LL_DMA_PERIPH_NOINCREMENT);

  LL_DMA_SetMemoryIncMode(DMA1, LL_DMA_STREAM_1, LL_DMA_MEMORY_INCREMENT);

  LL_DMA_SetPeriphSize(DMA1, LL_DMA_STREAM_1, LL_DMA_PDATAALIGN_BYTE);

  LL_DMA_SetMemorySize(DMA1, LL_DMA_STREAM_1, LL_DMA_MDATAALIGN_BYTE);

  LL_DMA_DisableFifoMode(DMA1, LL_DMA_STREAM_1);

  /* USART3_TX Init */
  LL_DMA_SetChannelSelection(DMA1, LL_DMA_STREAM_3, LL_DMA_CHANNEL_4);

  LL_DMA_SetDataTransferDirection(DMA1, LL_DMA_STREAM_3, LL_DMA_DIRECTION_MEMORY_TO_PERIPH);

  LL_DMA_SetStreamPriorityLevel(DMA1, LL_DMA_STREAM_3, LL_DMA_PRIORITY_LOW);

  LL_DMA_SetMode(DMA1, LL_DMA_STREAM_3, LL_DMA_MODE_NORMAL);

  LL_DMA_SetPeriphIncMode(DMA1, LL_DMA_STREAM_3, LL_DMA_PERIPH_NOINCREMENT);

  LL_DMA_SetMemoryIncMode(DMA1, LL_DMA_STREAM_3, LL_DMA_MEMORY_INCREMENT);

  LL_DMA_SetPeriphSize(DMA1, LL_DMA_STREAM_3, LL_DMA_PDATAALIGN_BYTE);

  LL_DMA_SetMemorySize(DMA1, LL_DMA_STREAM_3, LL_DMA_MDATAALIGN_BYTE);

  LL_DMA_DisableFifoMode(DMA1, LL_DMA_STREAM_3);

  USART_InitStruct.BaudRate = 115200;
  USART_InitStruct.DataWidth = LL_USART_DATAWIDTH_8B;
  USART_InitStruct.StopBits = LL_USART_STOPBITS_1;
  USART_InitStruct.Parity = LL_USART_PARITY_NONE;
  USART_InitStruct.TransferDirection = LL_USART_DIRECTION_TX_RX;
  USART_InitStruct.HardwareFlowControl = LL_USART_HWCONTROL_NONE;
  USART_InitStruct.OverSampling = LL_USART_OVERSAMPLING_16;
  LL_USART_Init(USART3, &USART_InitStruct);
  LL_USART_ConfigAsyncMode(USART3);
  LL_USART_Enable(USART3);

}

static void MX_USART6_UART_Init(void)
{

  LL_USART_InitTypeDef USART_InitStruct = {0};

  LL_GPIO_InitTypeDef GPIO_InitStruct = {0};

  /* Peripheral clock enable */
  LL_APB2_GRP1_EnableClock(LL_APB2_GRP1_PERIPH_USART6);

  LL_AHB1_GRP1_EnableClock(LL_AHB1_GRP1_PERIPH_GPIOC);
  /**USART6 GPIO Configuration
  PC6   ------> USART6_TX
  PC7   ------> USART6_RX
  */
  GPIO_InitStruct.Pin = LL_GPIO_PIN_6|LL_GPIO_PIN_7;
  GPIO_InitStruct.Mode = LL_GPIO_MODE_ALTERNATE;
  GPIO_InitStruct.Speed = LL_GPIO_SPEED_FREQ_VERY_HIGH;
  GPIO_InitStruct.OutputType = LL_GPIO_OUTPUT_PUSHPULL;
  GPIO_InitStruct.Pull = LL_GPIO_PULL_NO;
  GPIO_InitStruct.Alternate = LL_GPIO_AF_8;
  LL_GPIO_Init(GPIOC, &GPIO_InitStruct);

  /* USART6 DMA Init */

  /* USART6_RX Init */
  LL_DMA_SetChannelSelection(DMA2, LL_DMA_STREAM_1, LL_DMA_CHANNEL_5);

  LL_DMA_SetDataTransferDirection(DMA2, LL_DMA_STREAM_1, LL_DMA_DIRECTION_PERIPH_TO_MEMORY);

  LL_DMA_SetStreamPriorityLevel(DMA2, LL_DMA_STREAM_1, LL_DMA_PRIORITY_LOW);

  LL_DMA_SetMode(DMA2, LL_DMA_STREAM_1, LL_DMA_MODE_NORMAL);

  LL_DMA_SetPeriphIncMode(DMA2, LL_DMA_STREAM_1, LL_DMA_PERIPH_NOINCREMENT);

  LL_DMA_SetMemoryIncMode(DMA2, LL_DMA_STREAM_1, LL_DMA_MEMORY_INCREMENT);

  LL_DMA_SetPeriphSize(DMA2, LL_DMA_STREAM_1, LL_DMA_PDATAALIGN_BYTE);

  LL_DMA_SetMemorySize(DMA2, LL_DMA_STREAM_1, LL_DMA_MDATAALIGN_BYTE);

  LL_DMA_DisableFifoMode(DMA2, LL_DMA_STREAM_1);

  USART_InitStruct.BaudRate = 115200;
  USART_InitStruct.DataWidth = LL_USART_DATAWIDTH_8B;
  USART_InitStruct.StopBits = LL_USART_STOPBITS_1;
  USART_InitStruct.Parity = LL_USART_PARITY_NONE;
  USART_InitStruct.TransferDirection = LL_USART_DIRECTION_TX_RX;
  USART_InitStruct.HardwareFlowControl = LL_USART_HWCONTROL_NONE;
  USART_InitStruct.OverSampling = LL_USART_OVERSAMPLING_16;
  LL_USART_Init(USART6, &USART_InitStruct);
  LL_USART_ConfigAsyncMode(USART6);
  LL_USART_Enable(USART6);

}

static void MX_DMA_Init(void)
{

  /* Init with LL driver */
  /* DMA controller clock enable */
  LL_AHB1_GRP1_EnableClock(LL_AHB1_GRP1_PERIPH_DMA2);
  LL_AHB1_GRP1_EnableClock(LL_AHB1_GRP1_PERIPH_DMA1);

  /* DMA interrupt init */
  /* DMA1_Stream0_IRQn interrupt configuration */
  NVIC_SetPriority(DMA1_Stream0_IRQn, NVIC_EncodePriority(NVIC_GetPriorityGrouping(),5, 0));
  NVIC_EnableIRQ(DMA1_Stream0_IRQn);
  /* DMA1_Stream1_IRQn interrupt configuration */
  NVIC_SetPriority(DMA1_Stream1_IRQn, NVIC_EncodePriority(NVIC_GetPriorityGrouping(),5, 0));
  NVIC_EnableIRQ(DMA1_Stream1_IRQn);
  /* DMA1_Stream2_IRQn interrupt configuration */
  NVIC_SetPriority(DMA1_Stream2_IRQn, NVIC_EncodePriority(NVIC_GetPriorityGrouping(),5, 0));
  NVIC_EnableIRQ(DMA1_Stream2_IRQn);
  /* DMA1_Stream3_IRQn interrupt configuration */
  NVIC_SetPriority(DMA1_Stream3_IRQn, NVIC_EncodePriority(NVIC_GetPriorityGrouping(),5, 0));
  NVIC_EnableIRQ(DMA1_Stream3_IRQn);
  /* DMA1_Stream4_IRQn interrupt configuration */
  NVIC_SetPriority(DMA1_Stream4_IRQn, NVIC_EncodePriority(NVIC_GetPriorityGrouping(),5, 0));
  NVIC_EnableIRQ(DMA1_Stream4_IRQn);
  /* DMA1_Stream5_IRQn interrupt configuration */
  NVIC_SetPriority(DMA1_Stream5_IRQn, NVIC_EncodePriority(NVIC_GetPriorityGrouping(),5, 0));
  NVIC_EnableIRQ(DMA1_Stream5_IRQn);
  /* DMA1_Stream6_IRQn interrupt configuration */
  NVIC_SetPriority(DMA1_Stream6_IRQn, NVIC_EncodePriority(NVIC_GetPriorityGrouping(),5, 0));
  NVIC_EnableIRQ(DMA1_Stream6_IRQn);
  /* DMA1_Stream7_IRQn interrupt configuration */
  NVIC_SetPriority(DMA1_Stream7_IRQn, NVIC_EncodePriority(NVIC_GetPriorityGrouping(),5, 0));
  NVIC_EnableIRQ(DMA1_Stream7_IRQn);
  /* DMA2_Stream0_IRQn interrupt configuration */
  NVIC_SetPriority(DMA2_Stream0_IRQn, NVIC_EncodePriority(NVIC_GetPriorityGrouping(),5, 0));
  NVIC_EnableIRQ(DMA2_Stream0_IRQn);
  /* DMA2_Stream1_IRQn interrupt configuration */
  NVIC_SetPriority(DMA2_Stream1_IRQn, NVIC_EncodePriority(NVIC_GetPriorityGrouping(),5, 0));
  NVIC_EnableIRQ(DMA2_Stream1_IRQn);
  /* DMA2_Stream2_IRQn interrupt configuration */
  NVIC_SetPriority(DMA2_Stream2_IRQn, NVIC_EncodePriority(NVIC_GetPriorityGrouping(),5, 0));
  NVIC_EnableIRQ(DMA2_Stream2_IRQn);
  /* DMA2_Stream7_IRQn interrupt configuration */
  NVIC_SetPriority(DMA2_Stream7_IRQn, NVIC_EncodePriority(NVIC_GetPriorityGrouping(),5, 0));
  NVIC_EnableIRQ(DMA2_Stream7_IRQn);

}

static void MX_GPIO_Init(void)
{
  LL_GPIO_InitTypeDef GPIO_InitStruct = {0};

  /* GPIO Ports Clock Enable */
  LL_AHB1_GRP1_EnableClock(LL_AHB1_GRP1_PERIPH_GPIOC);
  LL_AHB1_GRP1_EnableClock(LL_AHB1_GRP1_PERIPH_GPIOH);
  LL_AHB1_GRP1_EnableClock(LL_AHB1_GRP1_PERIPH_GPIOA);
  LL_AHB1_GRP1_EnableClock(LL_AHB1_GRP1_PERIPH_GPIOB);
  LL_AHB1_GRP1_EnableClock(LL_AHB1_GRP1_PERIPH_GPIOE);
  LL_AHB1_GRP1_EnableClock(LL_AHB1_GRP1_PERIPH_GPIOD);

  /**/
  LL_GPIO_ResetOutputPin(GPIOC, LL_GPIO_PIN_1|LL_GPIO_PIN_9);

  /**/
  LL_GPIO_ResetOutputPin(GPIOE, LL_GPIO_PIN_14);

  /**/
  LL_GPIO_ResetOutputPin(GPIOD, LL_GPIO_PIN_15|LL_GPIO_PIN_5|LL_GPIO_PIN_6);

  /**/
  LL_GPIO_ResetOutputPin(GPIOA, LL_GPIO_PIN_8);

  /**/
  LL_GPIO_SetOutputPin(GPIOE, LL_GPIO_PIN_15);

  /**/
  LL_GPIO_SetOutputPin(GPIOC, LL_GPIO_PIN_8);

  /**/
  GPIO_InitStruct.Pin = LL_GPIO_PIN_1;
  GPIO_InitStruct.Mode = LL_GPIO_MODE_OUTPUT;
  GPIO_InitStruct.Speed = LL_GPIO_SPEED_FREQ_LOW;
  GPIO_InitStruct.OutputType = LL_GPIO_OUTPUT_PUSHPULL;
  GPIO_InitStruct.Pull = LL_GPIO_PULL_NO;
  LL_GPIO_Init(GPIOC, &GPIO_InitStruct);

  /**/
  GPIO_InitStruct.Pin = LL_GPIO_PIN_13;
  GPIO_InitStruct.Mode = LL_GPIO_MODE_INPUT;
  GPIO_InitStruct.Pull = LL_GPIO_PULL_DOWN;
  LL_GPIO_Init(GPIOE, &GPIO_InitStruct);

  /**/
  GPIO_InitStruct.Pin = LL_GPIO_PIN_14|LL_GPIO_PIN_15;
  GPIO_InitStruct.Mode = LL_GPIO_MODE_OUTPUT;
  GPIO_InitStruct.Speed = LL_GPIO_SPEED_FREQ_LOW;
  GPIO_InitStruct.OutputType = LL_GPIO_OUTPUT_PUSHPULL;
  GPIO_InitStruct.Pull = LL_GPIO_PULL_DOWN;
  LL_GPIO_Init(GPIOE, &GPIO_InitStruct);

  /**/
  GPIO_InitStruct.Pin = LL_GPIO_PIN_15;
  GPIO_InitStruct.Mode = LL_GPIO_MODE_OUTPUT;
  GPIO_InitStruct.Speed = LL_GPIO_SPEED_FREQ_LOW;
  GPIO_InitStruct.OutputType = LL_GPIO_OUTPUT_PUSHPULL;
  GPIO_InitStruct.Pull = LL_GPIO_PULL_NO;
  LL_GPIO_Init(GPIOD, &GPIO_InitStruct);

  /**/
  GPIO_InitStruct.Pin = LL_GPIO_PIN_8;
  GPIO_InitStruct.Mode = LL_GPIO_MODE_OUTPUT;
  GPIO_InitStruct.Speed = LL_GPIO_SPEED_FREQ_LOW;
  GPIO_InitStruct.OutputType = LL_GPIO_OUTPUT_PUSHPULL;
  GPIO_InitStruct.Pull = LL_GPIO_PULL_UP;
  LL_GPIO_Init(GPIOC, &GPIO_InitStruct);

  /**/
  GPIO_InitStruct.Pin = LL_GPIO_PIN_9;
  GPIO_InitStruct.Mode = LL_GPIO_MODE_OUTPUT;
  GPIO_InitStruct.Speed = LL_GPIO_SPEED_FREQ_LOW;
  GPIO_InitStruct.OutputType = LL_GPIO_OUTPUT_PUSHPULL;
  GPIO_InitStruct.Pull = LL_GPIO_PULL_DOWN;
  LL_GPIO_Init(GPIOC, &GPIO_InitStruct);

  /**/
  GPIO_InitStruct.Pin = LL_GPIO_PIN_8;
  GPIO_InitStruct.Mode = LL_GPIO_MODE_OUTPUT;
  GPIO_InitStruct.Speed = LL_GPIO_SPEED_FREQ_LOW;
  GPIO_InitStruct.OutputType = LL_GPIO_OUTPUT_PUSHPULL;
  GPIO_InitStruct.Pull = LL_GPIO_PULL_DOWN;
  LL_GPIO_Init(GPIOA, &GPIO_InitStruct);

  /**/
  GPIO_InitStruct.Pin = LL_GPIO_PIN_3|LL_GPIO_PIN_4;
  GPIO_InitStruct.Mode = LL_GPIO_MODE_INPUT;
  GPIO_InitStruct.Pull = LL_GPIO_PULL_DOWN;
  LL_GPIO_Init(GPIOD, &GPIO_InitStruct);

  /**/
  GPIO_InitStruct.Pin = LL_GPIO_PIN_5|LL_GPIO_PIN_6;
  GPIO_InitStruct.Mode = LL_GPIO_MODE_OUTPUT;
  GPIO_InitStruct.Speed = LL_GPIO_SPEED_FREQ_LOW;
  GPIO_InitStruct.OutputType = LL_GPIO_OUTPUT_PUSHPULL;
  GPIO_InitStruct.Pull = LL_GPIO_PULL_DOWN;
  LL_GPIO_Init(GPIOD, &GPIO_InitStruct);

}

void StartDefaultTask(void const * argument)
{
  /* USER CODE BEGIN 5 */
  /* Infinite loop */
//  for(;;)
//  {
//    osDelay(1);
//  }
	AppMain();
  /* USER CODE END 5 */
}

void HAL_TIM_PeriodElapsedCallback(TIM_HandleTypeDef *htim)
{
  if (htim->Instance == TIM14) {
    HAL_IncTick();
  }
}

void Error_Handler(void)
{
  __disable_irq();
  while (1)
  {
  }
}
